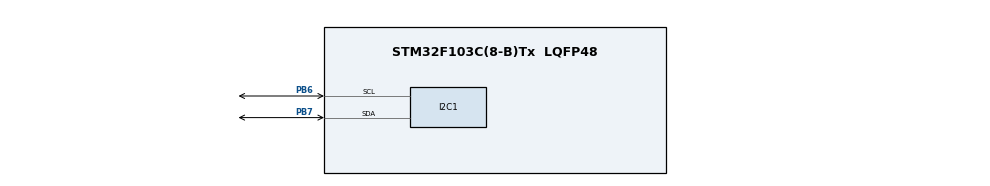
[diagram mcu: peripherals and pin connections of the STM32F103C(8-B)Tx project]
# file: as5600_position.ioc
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Mcu.Family=STM32F1
Mcu.Name=STM32F103C(8-B)Tx
Mcu.Package=LQFP48
NVIC.I2C1_ER_IRQn=true\:0\:0\:false\:false\:true\:true\:true\:true
NVIC.I2C1_EV_IRQn=true\:0\:0\:false\:false\:true\:true\:true\:true
NVIC.PriorityGroup=NVIC_PRIORITYGROUP_4
NVIC.TIM2_IRQn=true\:0\:0\:false\:false\:true\:true\:true\:true
PA13.Mode=Serial_Wire
PA13.Signal=SYS_JTMS-SWDIO
PA14.Mode=Serial_Wire
PA14.Signal=SYS_JTCK-SWCLK
PB6.Mode=I2C
PB6.Signal=I2C1_SCL
PB7.Mode=I2C
PB7.Signal=I2C1_SDA
ProjectManager.HeapSize=0x200
ProjectManager.StackSize=0x400
ProjectManager.TargetToolchain=STM32CubeIDE
RCC.APB1Freq_Value=8000000
RCC.APB2Freq_Value=8000000
TIM2.Period=9
TIM2.Prescaler=7999
VP_TIM2_VS_ClockSourceINT.Mode=Internal
board=custom

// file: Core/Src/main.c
/* USER CODE BEGIN Header */
/**
  ******************************************************************************
  * @file           : main.c
  * @brief          : Main program body
  ******************************************************************************
  * @attention
  *
  * Copyright (c) 2025 STMicroelectronics.
  * All rights reserved.
  *
  * This software is licensed under terms that can be found in the LICENSE file
  * in the root directory of this software component.
  * If no LICENSE file comes with this software, it is provided AS-IS.
  *
  ******************************************************************************
  */
/* USER CODE END Header */
#include "main.h"
#include "i2c.h"
#include "tim.h"
#include "gpio.h"

/* USER CODE BEGIN Includes */
#include "as5600.h"
/* USER CODE END Includes */

/* USER CODE BEGIN PV */
volatile uint16_t raw_angle;
volatile uint16_t status_reg;
volatile float angle_degrees;
volatile uint8_t sensor_data_ready = 0;
/* USER CODE END PV */

void SystemClock_Config(void);
/* USER CODE BEGIN PFP */
void as5600_write(uint8_t reg, uint8_t value);
uint16_t as5600_read_angle(void);
uint8_t as5600_read_status(void);
void as5600_init(void);
void process_sensor_data(void);
/* USER CODE END PFP */

int main(void)
{

  /* MCU Configuration--------------------------------------------------------*/

  /* Reset of all peripherals, Initializes the Flash interface and the Systick. */
  HAL_Init();

  /* Configure the system clock */
  SystemClock_Config();

  /* Initialize all configured peripherals */
  MX_GPIO_Init();
  MX_I2C1_Init();
  MX_TIM2_Init();
  /* USER CODE BEGIN 2 */
  as5600_init();

  // Start timer interrupt for sensor reading (100Hz - every 10ms)
  HAL_TIM_Base_Start_IT(&htim2);
  /* USER CODE END 2 */

  /* Infinite loop */
  /* USER CODE BEGIN WHILE */
  while (1)
  {
	  // Check if new sensor data is available
	  if (sensor_data_ready)
	  {
		  sensor_data_ready = 0;  // Clear flag
		  process_sensor_data();

		  // Here you can process the angle data, send via UART, etc.
		  // The actual sensor reading happens in the interrupt
	  }

	  // Main loop can do other tasks while sensor reading happens in background
	  // HAL_Delay(1);  // Optional small delay or remove for maximum responsiveness
    /* USER CODE END WHILE */

  }
}

void SystemClock_Config(void)
{
  RCC_OscInitTypeDef RCC_OscInitStruct = {0};
  RCC_ClkInitTypeDef RCC_ClkInitStruct = {0};

  /** Initializes the RCC Oscillators according to the specified parameters
  * in the RCC_OscInitTypeDef structure.
  */
  RCC_OscInitStruct.OscillatorType = RCC_OSCILLATORTYPE_HSI;
  RCC_OscInitStruct.HSIState = RCC_HSI_ON;
  RCC_OscInitStruct.HSICalibrationValue = RCC_HSICALIBRATION_DEFAULT;
  RCC_OscInitStruct.PLL.PLLState = RCC_PLL_NONE;
  if (HAL_RCC_OscConfig(&RCC_OscInitStruct) != HAL_OK)
  {
    Error_Handler();
  }

  /** Initializes the CPU, AHB and APB buses clocks
  */
  RCC_ClkInitStruct.ClockType = RCC_CLOCKTYPE_HCLK|RCC_CLOCKTYPE_SYSCLK
                              |RCC_CLOCKTYPE_PCLK1|RCC_CLOCKTYPE_PCLK2;
  RCC_ClkInitStruct.SYSCLKSource = RCC_SYSCLKSOURCE_HSI;
  RCC_ClkInitStruct.AHBCLKDivider = RCC_SYSCLK_DIV1;
  RCC_ClkInitStruct.APB1CLKDivider = RCC_HCLK_DIV1;
  RCC_ClkInitStruct.APB2CLKDivider = RCC_HCLK_DIV1;

  if (HAL_RCC_ClockConfig(&RCC_ClkInitStruct, FLASH_LATENCY_0) != HAL_OK)
  {
    Error_Handler();
  }
}

/* USER CODE BEGIN 4 */
// Timer interrupt callback - called every 10ms (100Hz)
void HAL_TIM_PeriodElapsedCallback(TIM_HandleTypeDef *htim)
{
    if (htim->Instance == TIM2)
    {
        // Read sensor data in interrupt
        raw_angle = as5600_read_angle();
        status_reg = as5600_read_status();

        // Set flag to process data in main loop
        sensor_data_ready = 1;
    }
}

void process_sensor_data(void)
{
    // Convert raw angle to degrees (0-360°)
    angle_degrees = (raw_angle * 360.0f) / 4096.0f;

    // Additional processing can be done here
    // For example: filtering, averaging, sending data via UART, etc.
}
/* USER CODE END 4 */

void Error_Handler(void)
{
  __disable_irq();
  while (1)
  {
  }
}
